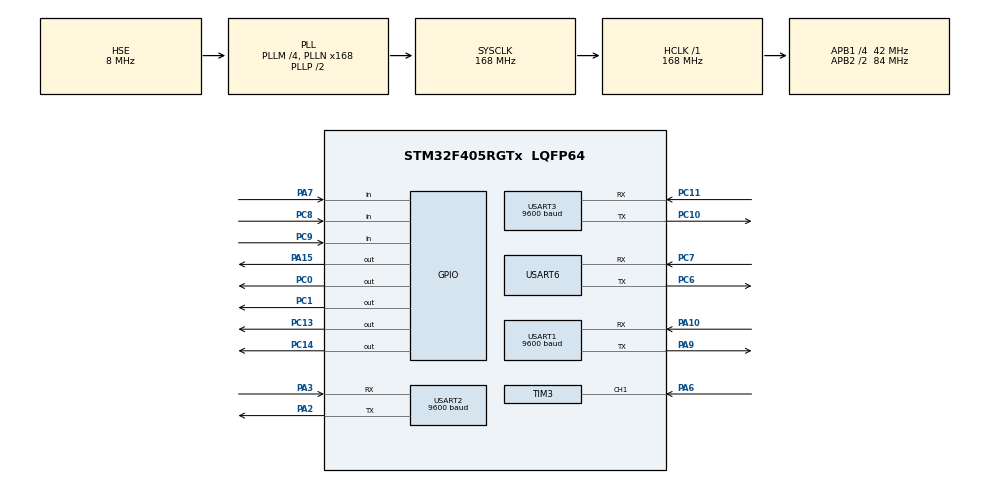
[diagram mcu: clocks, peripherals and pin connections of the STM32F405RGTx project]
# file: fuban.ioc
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Mcu.Family=STM32F4
NVIC.USART3_IRQn=true\:0\:0\:false\:false\:true\:true\:true
PH0-OSC_IN.Signal=RCC_OSC_IN
RCC.CortexFreq_Value=168000000
USART1.BaudRate=9600
PC10.Signal=USART3_TX
Dma.USART1_RX.3.MemDataAlignment=DMA_MDATAALIGN_BYTE
Dma.USART2_RX.1.MemDataAlignment=DMA_MDATAALIGN_BYTE
RCC.SYSCLKSource=RCC_SYSCLKSOURCE_PLLCLK
ProjectManager.StackSize=0x400
Dma.USART3_RX.2.Priority=DMA_PRIORITY_LOW
Dma.USART6_RX.0.Instance=DMA2_Stream1
Dma.USART6_RX.0.FIFOMode=DMA_FIFOMODE_DISABLE
USART3.BaudRate=9600
Dma.USART6_RX.0.Direction=DMA_PERIPH_TO_MEMORY
Dma.USART1_RX.3.FIFOMode=DMA_FIFOMODE_DISABLE
Dma.USART3_RX.2.PeriphInc=DMA_PINC_DISABLE
RCC.HCLKFreq_Value=168000000
RCC.APB2TimFreq_Value=168000000
TIM3.Period=0xFFFF
PC7.Signal=USART6_RX
Dma.USART2_RX.1.PeriphInc=DMA_PINC_DISABLE
Dma.USART2_RX.1.MemInc=DMA_MINC_ENABLE
RCC.AHBFreq_Value=168000000
PH0-OSC_IN.Mode=HSE-External-Oscillator
RCC.HSE_VALUE=8000000
TIM3.Channel-Input_Capture1_from_TI1=TIM_CHANNEL_1
PC13-ANTI_TAMP.Signal=GPIO_Output
PC1.GPIO_PuPd=GPIO_PULLUP
USART6.WordLength=WORDLENGTH_9B
TIM3.Prescaler=84-1
Dma.USART1_RX.3.Direction=DMA_PERIPH_TO_MEMORY
SH.S_TIM3_CH1.0=TIM3_CH1,Input_Capture1_from_TI1
TIM4.Period=9999
PH1-OSC_OUT.Mode=HSE-External-Oscillator
Mcu.Package=LQFP64
PA6.Signal=S_TIM3_CH1
Dma.USART1_RX.3.Instance=DMA2_Stream2
USART2.VirtualMode=VM_ASYNC
USART6.VirtualMode=VM_ASYNC
PA10.Signal=USART1_RX
Dma.USART6_RX.0.Mode=DMA_NORMAL
PA15.Signal=GPIO_Output
PC11.Mode=Asynchronous
Dma.USART6_RX.0.MemDataAlignment=DMA_MDATAALIGN_BYTE
RCC.APB2CLKDivider=RCC_HCLK_DIV2
NVIC.DMA2_Stream2_IRQn=true\:0\:0\:false\:false\:true\:false\:true
Dma.Request2=USART3_RX
Dma.Request1=USART2_RX
RCC.APB1TimFreq_Value=84000000
Dma.Request3=USART1_RX
PC0.GPIO_PuPd=GPIO_PULLUP
NVIC.USART1_IRQn=true\:0\:0\:false\:false\:true\:true\:true
Dma.USART2_RX.1.Mode=DMA_NORMAL
Dma.Request0=USART6_RX
Dma.USART1_RX.3.MemInc=DMA_MINC_ENABLE
VP_TIM3_VS_ClockSourceINT.Mode=Internal
PA3.Signal=USART2_RX
RCC.PLLSourceVirtual=RCC_PLLSOURCE_HSE
Dma.USART2_RX.1.Priority=DMA_PRIORITY_VERY_HIGH
TIM4.AutoReloadPreload=TIM_AUTORELOAD_PRELOAD_ENABLE
Dma.USART2_RX.1.FIFOMode=DMA_FIFOMODE_DISABLE
PA10.Mode=Asynchronous
Dma.USART6_RX.0.PeriphInc=DMA_PINC_DISABLE
PC13-ANTI_TAMP.GPIO_PuPd=GPIO_PULLUP
Dma.USART3_RX.2.Mode=DMA_NORMAL
Dma.USART1_RX.3.PeriphInc=DMA_PINC_DISABLE
PC11.Signal=USART3_RX
PC8.Signal=GPIO_Input
PC6.Signal=USART6_TX
PC10.Mode=Asynchronous
NVIC.DMA1_Stream1_IRQn=true\:0\:0\:false\:false\:true\:false\:true
NVIC.DMA2_Stream1_IRQn=true\:0\:0\:false\:false\:true\:false\:true
PC0.Signal=GPIO_Output
RCC.APB1CLKDivider=RCC_HCLK_DIV4
PC14-OSC32_IN.Signal=GPIO_Output
NVIC.USART2_IRQn=true\:1\:0\:true\:false\:true\:true\:true
USART2.BaudRate=9600
NVIC.USART6_IRQn=true\:0\:0\:false\:false\:true\:true\:true
PA3.Mode=Asynchronous
PA9.Mode=Asynchronous
Dma.USART3_RX.2.PeriphDataAlignment=DMA_PDATAALIGN_BYTE
Dma.USART3_RX.2.MemInc=DMA_MINC_ENABLE
ProjectManager.TargetToolchain=MDK-ARM V5.27
NVIC.DMA1_Stream5_IRQn=true\:1\:0\:true\:false\:true\:false\:true
PC6.Mode=Asynchronous
PA9.Signal=USART1_TX
TIM4.Prescaler=83
Dma.USART3_RX.2.Direction=DMA_PERIPH_TO_MEMORY
RCC.LSE_VALUE=32768
PA7.GPIO_PuPd=GPIO_PULLUP
Dma.USART2_RX.1.Instance=DMA1_Stream5
Dma.USART2_RX.1.Direction=DMA_PERIPH_TO_MEMORY
Dma.USART2_RX.1.PeriphDataAlignment=DMA_PDATAALIGN_BYTE
board=custom
RCC.VCOOutputFreq_Value=336000000
NVIC.TIM3_IRQn=true\:0\:0\:false\:false\:true\:true\:true
RCC.APB2Freq_Value=84000000
PC9.GPIO_PuPd=GPIO_PULLUP
PH1-OSC_OUT.Signal=RCC_OSC_OUT
Dma.USART1_RX.3.PeriphDataAlignment=DMA_PDATAALIGN_BYTE
Mcu.Name=STM32F405RGTx
PA2.Signal=USART2_TX
Dma.USART1_RX.3.Priority=DMA_PRIORITY_LOW
RCC.48MHZClocksFreq_Value=84000000
PC8.GPIO_PuPd=GPIO_PULLUP
RCC.SYSCLKFreq_VALUE=168000000
Dma.USART6_RX.0.PeriphDataAlignment=DMA_PDATAALIGN_BYTE
USART3.VirtualMode=VM_ASYNC
USART1.VirtualMode=VM_ASYNC
ProjectManager.HeapSize=0x200
Dma.USART3_RX.2.FIFOMode=DMA_FIFOMODE_DISABLE
RCC.HSI_VALUE=16000000
Dma.USART6_RX.0.Priority=DMA_PRIORITY_HIGH
VP_TIM4_VS_ClockSourceINT.Mode=Internal
Dma.USART3_RX.2.MemDataAlignment=DMA_MDATAALIGN_BYTE
NVIC.PriorityGroup=NVIC_PRIORITYGROUP_4
Dma.USART6_RX.0.MemInc=DMA_MINC_ENABLE
RCC.PLLM=4
RCC.PLLN=168
PA15.GPIO_PuPd=GPIO_PULLUP
PA2.Mode=Asynchronous
PC14-OSC32_IN.GPIO_PuPd=GPIO_PULLUP
PC9.Signal=GPIO_Input
Dma.USART3_RX.2.Instance=DMA1_Stream1
PC7.Mode=Asynchronous
NVIC.TIM4_IRQn=true\:0\:0\:false\:false\:true\:true\:true
RCC.APB1Freq_Value=42000000
Dma.USART1_RX.3.Mode=DMA_NORMAL
PC1.Signal=GPIO_Output
PA7.Signal=GPIO_Input

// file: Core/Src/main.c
/* USER CODE BEGIN Header */
/**
  ******************************************************************************
  * @file           : main.c
  * @brief          : Main program body
  ******************************************************************************
  * @attention
  *
  * <h2><center>&copy; Copyright (c) 2021 STMicroelectronics.
  * All rights reserved.</center></h2>
  *
  * This software component is licensed by ST under BSD 3-Clause license,
  * the "License"; You may not use this file except in compliance with the
  * License. You may obtain a copy of the License at:
  *                        opensource.org/licenses/BSD-3-Clause
  *
  ******************************************************************************
  */
/* USER CODE END Header */
#include "main.h"
#include "dma.h"
#include "tim.h"
#include "usart.h"
#include "gpio.h"

void SystemClock_Config(void);

/* USER CODE BEGIN 0 */
extern uint8_t Uart_Rx[5];
extern uint8_t GY_1_Uart_Rx[8];
extern uint8_t GY_2_Uart_Rx[8];//������һ���ṹ�������װ����
extern uint8_t GY_0_Uart_Rx[8];
/* USER CODE END 0 */

int main(void)
{

  /* MCU Configuration--------------------------------------------------------*/

  /* Reset of all peripherals, Initializes the Flash interface and the Systick. */
  HAL_Init();

  /* Configure the system clock */
  SystemClock_Config();

  /* Initialize all configured peripherals */
  MX_GPIO_Init();
  MX_DMA_Init();
  MX_USART6_UART_Init();
  MX_USART2_UART_Init();
  MX_USART3_UART_Init();
  MX_TIM4_Init();
  MX_USART1_UART_Init();
  MX_TIM3_Init();
  /* USER CODE BEGIN 2 */
	HAL_TIM_Base_Start_IT(&htim4);
	Uart1_All_Init_6();
	Uart1_All_Init_3();
	Uart1_All_Init_2();
  /* USER CODE END 2 */

  /* Infinite loop */
  while (1)
  {

  }
}

void SystemClock_Config(void)
{
  RCC_OscInitTypeDef RCC_OscInitStruct = {0};
  RCC_ClkInitTypeDef RCC_ClkInitStruct = {0};

  /** Configure the main internal regulator output voltage
  */
  __HAL_RCC_PWR_CLK_ENABLE();
  __HAL_PWR_VOLTAGESCALING_CONFIG(PWR_REGULATOR_VOLTAGE_SCALE1);
  /** Initializes the RCC Oscillators according to the specified parameters
  * in the RCC_OscInitTypeDef structure.
  */
  RCC_OscInitStruct.OscillatorType = RCC_OSCILLATORTYPE_HSE;
  RCC_OscInitStruct.HSEState = RCC_HSE_ON;
  RCC_OscInitStruct.PLL.PLLState = RCC_PLL_ON;
  RCC_OscInitStruct.PLL.PLLSource = RCC_PLLSOURCE_HSE;
  RCC_OscInitStruct.PLL.PLLM = 4;
  RCC_OscInitStruct.PLL.PLLN = 168;
  RCC_OscInitStruct.PLL.PLLP = RCC_PLLP_DIV2;
  RCC_OscInitStruct.PLL.PLLQ = 4;
  if (HAL_RCC_OscConfig(&RCC_OscInitStruct) != HAL_OK)
  {
    Error_Handler();
  }
  /** Initializes the CPU, AHB and APB buses clocks
  */
  RCC_ClkInitStruct.ClockType = RCC_CLOCKTYPE_HCLK|RCC_CLOCKTYPE_SYSCLK
                              |RCC_CLOCKTYPE_PCLK1|RCC_CLOCKTYPE_PCLK2;
  RCC_ClkInitStruct.SYSCLKSource = RCC_SYSCLKSOURCE_PLLCLK;
  RCC_ClkInitStruct.AHBCLKDivider = RCC_SYSCLK_DIV1;
  RCC_ClkInitStruct.APB1CLKDivider = RCC_HCLK_DIV4;
  RCC_ClkInitStruct.APB2CLKDivider = RCC_HCLK_DIV2;

  if (HAL_RCC_ClockConfig(&RCC_ClkInitStruct, FLASH_LATENCY_5) != HAL_OK)
  {
    Error_Handler();
  }
}

void Error_Handler(void)
{
  __disable_irq();
  while (1)
  {
  }
}

/************************ (C) COPYRIGHT STMicroelectronics *****END OF FILE****/
